# M460_v1 register map
File version: 1.0
Registers are 32-bit, read-write, reset 0x0 unless marked. A register's access mark holds for its fields unless they carry their own. Offsets are from the block's base; [hi:lo] are bit positions; {n}, {i} and the like mark numbered series; 'fields as' and 'values as' point back to an identical list.

## SYS (part 1 of 2) — SYS Register Map
Base 0x40000000
0x00 SYS_PDID ro reset 0x451A93 — Part Device Identification Number Register
  [31:0] PDID — Part Device Identification Number (Read Only). This register reflects device part number code. Software can read this register to identify which device is used.
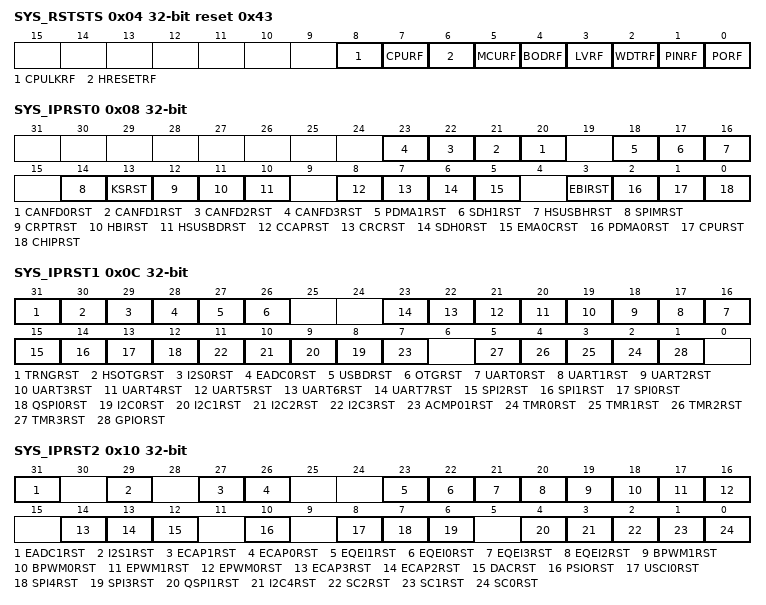
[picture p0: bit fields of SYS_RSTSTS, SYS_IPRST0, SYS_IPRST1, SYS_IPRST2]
0x04 SYS_RSTSTS reset 0x43 — System Reset Status Register
  [8] CPULKRF — CPU Lockup Reset Flag. Note 1: Write 1 to clear this bit to 0. Note 2: When CPU lockup happened under ICE is connected, this flag will set to 1 but chip will not reset.
    0=No reset from CPU lockup happened; 1=The Cortex-M4 lockup happened and chip is reset
  [7] CPURF — CPU Reset Flag. The CPU reset flag is set by hardware if software writes CPURST (SYS_IPRST0[1]) 1 to reset Cortex-M4 Core and Flash Memory Controller (FMC). Note: Write 1 to clear this bit to 0.
    0=No reset from CPU; 1=The Cortex-M4 Core and FMC are reset by software setting CPURST to 1
  [6] HRESETRF — HRESET Reset Flag. The HRESET reset flag is set by the 'Reset Signal' from the HRESET. Note 1: Write 1 to clear this bit to 0. Note 2: HRESET includes: POR, Reset Pin, LVR, BOD, WDT, WWDT, CPU lockup, CHIP and MCU reset.
    0=No reset from HRESET; 1=Reset from HRESET
  [5] MCURF — MCU Reset Flag. The MCU reset flag is set by the 'Reset Signal' from the Cortex-M4 Core to indicate the previous reset source. Note: Write 1 to clear this bit to 0.
    0=No reset from Cortex-M4; 1=The Cortex-M4 had issued the reset signal to reset the system by writing 1 to the bit SYSRESETREQ(AIRCR[2], Application Interrupt and Reset Control Register, address = 0xE000ED0C) in system control registers of Cortex-M4 core
  [4] BODRF — BOD Reset Flag. The BOD reset flag is set by the 'Reset Signal' from the Brown-Out Detector to indicate the previous reset source. Note: Write 1 to clear this bit to 0.
    0=No reset from BOD; 1=The BOD had issued the reset signal to reset the system
  [3] LVRF — LVR Reset Flag. The LVR reset flag is set by the 'Reset Signal' from the Low Voltage Reset Controller to indicate the previous reset source. Note: Write 1 to clear this bit to 0.
    0=No reset from LVR; 1=LVR controller had issued the reset signal to reset the system
  [2] WDTRF — WDT Reset Flag. The WDT reset flag is set by the 'Reset Signal' from the Watchdog Timer or Window Watchdog Timer to indicate the previous reset source. Note 1: Write 1 to clear this bit to 0. Note 2: Watchdog Timer register RSTF(WDT_CTL[2]) bit is set if the system has been reset by WDT time-out reset. Window Watchdog Timer register WWDTRF(WWDT_STATUS[1]) bit is set if the system has been reset by WWDT time-out reset.
    0=No reset from watchdog timer or window watchdog timer; 1=The watchdog timer or window watchdog timer had issued the reset signal to reset the system
  [1] PINRF — NRESET Pin Reset Flag. The nRESET pin reset flag is set by the 'Reset Signal' from the nRESET pin to indicate the previous reset source. Note: Write 1 to clear this bit to 0.
    0=No reset from nRESET pin; 1=Pin nRESET had issued the reset signal to reset the system
  [0] PORF — POR Reset Flag. The POR reset flag is set by the 'Reset Signal' from the Power-on Reset (POR) Controller or bit CHIPRST (SYS_IPRST0[0]) to indicate the previous reset source. Note: Write 1 to clear this bit to 0.
    0=No reset from POR or CHIPRST; 1=Power-on Reset (POR) or CHIPRST had issued the reset signal to reset the system
0x08 SYS_IPRST0 — Peripheral Reset Control Register 0
  [n+20] CANFD{n}RST (n=0..3) — CANFD{n} Controller Reset (Write Protect). Setting this bit to 1 will generate a reset signal to the CANFD{n} controller. User needs to set this bit to 0 to release from reset state. Note: This bit is write protected. Refer to the SYS_REGLCTL register.
    0=CANFD{n} controller normal operation; 1=CANFD{n} controller reset
  [18] PDMA1RST — PDMA1 Controller Reset (Write Protect). Setting this bit to 1 will generate a reset signal to the PDMA1 controller. User needs to set this bit to 0 to release from reset state. Note: This bit is write protected. Refer to the SYS_REGLCTL register.
    0=PDMA1 controller normal operation; 1=PDMA1 controller reset
  [17] SDH1RST — SDH1 Controller Reset (Write Protect). Setting this bit to 1 will generate a reset signal to the SDH1 controller. User needs to set this bit to 0 to release from the reset state. Note: This bit is write protected. Refer to the SYS_REGLCTL register.
    0=SDH1 controller normal operation; 1=SDH1 controller reset
  [16] HSUSBHRST — HSUSBH Controller Reset (Write Protect). Set this bit to 1 will generate a reset signal to the HSUSBH controller. User needs to set this bit to 0 to release from the reset state. Note: This bit is write protected. Refer to the SYS_REGLCTL register.
    0=HSUSBH controller normal operation; 1=HSUSBH controller reset
  [14] SPIMRST — SPIM Controller Reset (Write Protect). Setting this bit to 1 will generate a reset signal to the SPIM controller. User needs to set this bit to 0 to release from the reset state. Note: This bit is write protected. Refer to the SYS_REGLCTL register.
    0=SPIM controller normal operation; 1=SPIM controller reset
  [13] KSRST — Key Store Controller Reset (Write Protect). Setting this bit to 1 will generate a reset signal to the Key Store controller. User needs to set this bit to 0 to release from the reset state. Note: This bit is write protected. Refer to the SYS_REGLCTL register.
    0=Key Store controller normal operation; 1=Key Store controller reset
  [12] CRPTRST — CRYPTO Controller Reset (Write Protect). Setting this bit to 1 will generate a reset signal to the CRYPTO controller. User needs to set this bit to 0 to release from the reset state. Note: This bit is write protected. Refer to the SYS_REGLCTL register.
    0=CRYPTO controller normal operation; 1=CRYPTO controller reset
  [11] HBIRST — HBI Controller Reset (Write Protect). Setting this bit to 1 will generate a reset signal to the HBI controller. User needs to set this bit to 0 to release from the reset state. Note: This bit is write protected. Refer to the SYS_REGLCTL register.
    0=HBI controller normal operation; 1=HBI controller reset
  [10] HSUSBDRST — HSUSBD Controller Reset (Write Protect). Setting this bit to 1 will generate a reset signal to the HSUSBD controller. User needs to set this bit to 0 to release from the reset state.
    0=HSUSBD controller normal operation; 1=HSUSBD controller reset
  [8] CCAPRST — CCAP Controller Reset (Write Protect). Set this bit to 1 will generate a reset signal to the CCAP controller. User needs to set this bit to 0 to release from the reset state. Note: This bit is write protected. Refer to the SYS_REGLCTL register.
    0=CCAP controller normal operation; 1=CCAP controller reset
  [7] CRCRST — CRC Calculation Controller Reset (Write Protect). Set this bit to 1 will generate a reset signal to the CRC calculation controller. User needs to set this bit to 0 to release from the reset state. Note: This bit is write protected. Refer to the SYS_REGLCTL register.
    0=CRC calculation controller normal operation; 1=CRC calculation controller reset
  [6] SDH0RST — SDH0 Controller Reset (Write Protect). Setting this bit to 1 will generate a reset signal to the SDH0 controller. User needs to set this bit to 0 to release from the reset state. Note: This bit is write protected. Refer to the SYS_REGLCTL register.
    0=SDH0 controller normal operation; 1=SDH0 controller reset
  [5] EMA0CRST — EMAC0 Controller Reset (Write Protect). Setting this bit to 1 will generate a reset signal to the EMAC0 controller. User needs to set this bit to 0 to release from the reset state. Note: This bit is write protected. Refer to the SYS_REGLCTL register.
    0=EMAC0 controller normal operation; 1=EMAC0 controller reset
  [3] EBIRST — EBI Controller Reset (Write Protect). Set this bit to 1 will generate a reset signal to the EBI controller. User needs to set this bit to 0 to release from the reset state. Note: This bit is write protected. Refer to the SYS_REGLCTL register.
    0=EBI controller normal operation; 1=EBI controller reset
  [2] PDMA0RST — PDMA0 Controller Reset (Write Protect). Setting this bit to 1 will generate a reset signal to the PDMA0 controller. User needs to set this bit to 0 to release from reset state. Note: This bit is write protected. Refer to the SYS_REGLCTL register.
    0=PDMA0 controller normal operation; 1=PDMA0 controller reset
  [1] CPURST — Processor Core One-shot Reset (Write Protect). Setting this bit will only reset the processor core and Flash Memory Controller(FMC), and this bit will automatically return to 0 after the 2 clock cycles. Note: This bit is write protected. Refer to the SYS_REGLCTL register.
    0=Processor core normal operation; 1=Processor core one-shot reset
  [0] CHIPRST — Chip One-shot Reset (Write Protect). Setting this bit will reset the whole chip, including Processor core and all peripherals, and this bit will automatically return to 0 after the 2 clock cycles. The CHIPRST is same as the POR reset, all the chip controllers are reset and the chip setting from Flash are also reload. About the difference between CHIPRST and SYSRESETREQ(AIRCR[2]), please refer to System Reset section. Note: This bit is write protected. Refer to the SYS_REGLCTL register.
    0=Chip normal operation; 1=Chip one-shot reset
0x0C SYS_IPRST1 — Peripheral Reset Control Register 1
  [31] TRNGRST — TRNG Controller Reset
    0=TRNG controller normal operation; 1=TRNG controller reset
  [30] HSOTGRST — HSOTG Controller Reset
    0=HSOTG controller normal operation; 1=HSOTG controller reset
  [29] I2S0RST — I2S0 Controller Reset
    0=I2S0 controller normal operation; 1=I2S0 controller reset
  [28] EADC0RST — EADC0 Controller Reset
    0=EADC0 controller normal operation; 1=EADC0 controller reset
  [27] USBDRST — USBD Controller Reset
    0=USBD controller normal operation; 1=USBD controller reset
  [26] OTGRST — OTG Controller Reset
    0=OTG controller normal operation; 1=OTG controller reset
  [n+16] UART{n}RST (n=0..7) — UART{n} Controller Reset
    0=UART{n} controller normal operation; 1=UART{n} controller reset
  [15] SPI2RST — SPI2 Controller Reset
    0=SPI2 controller normal operation; 1=SPI2 controller reset
  [14] SPI1RST — SPI1 Controller Reset
    0=SPI1 controller normal operation; 1=SPI1 controller reset
  [13] SPI0RST — SPI0 Controller Reset
    0=SPI0 controller normal operation; 1=SPI0 controller reset
  [12] QSPI0RST — QSPI0 Controller Reset
    0=QSPI0 controller normal operation; 1=QSPI0 controller reset
  [n+8] I2C{n}RST (n=0..3) — I2C{n} Controller Reset
    0=I2C{n} controller normal operation; 1=I2C{n} controller reset
  [7] ACMP01RST — Analog Comparator 0/1 Controller Reset
    0=Analog Comparator 0/1 controller normal operation; 1=Analog Comparator 0/1 controller reset
  [n+2] TMR{n}RST (n=0..3) — Timer{n} Controller Reset
    0=Timer{n} controller normal operation; 1=Timer{n} controller reset
  [1] GPIORST — GPIO Controller Reset
    0=GPIO controller normal operation; 1=GPIO controller reset
0x10 SYS_IPRST2 — Peripheral Reset Control Register 2
  [31] EADC1RST — EADC1 Controller Reset
    0=EADC1 controller normal operation; 1=EADC1 controller reset
  [29] I2S1RST — I2S1 Controller Reset
    0=I2S1 controller normal operation; 1=I2S1 controller reset
  [27] ECAP1RST — ECAP1 Controller Reset
    0=ECAP1 controller normal operation; 1=ECAP1 controller reset
  [26] ECAP0RST — ECAP0 Controller Reset
    0=ECAP0 controller normal operation; 1=ECAP0 controller reset
  [23] EQEI1RST — EQEI1 Controller Reset
    0=EQEI1 controller normal operation; 1=EQEI1 controller reset
  [22] EQEI0RST — EQEI0 Controller Reset
    0=EQEI0 controller normal operation; 1=EQEI0 controller reset
  [21] EQEI3RST — EQEI3 Controller Reset
    0=EQEI3 controller normal operation; 1=EQEI3 controller reset
  [20] EQEI2RST — EQEI2 Controller Reset
    0=EQEI2 controller normal operation; 1=EQEI2 controller reset
  [19] BPWM1RST — BPWM1 Controller Reset
    0=BPWM1 controller normal operation; 1=BPWM1 controller reset
  [18] BPWM0RST — BPWM0 Controller Reset
    0=BPWM0 controller normal operation; 1=BPWM0 controller reset
  [17] EPWM1RST — EPWM1 Controller Reset
    0=EPWM1 controller normal operation; 1=EPWM1 controller reset
  [16] EPWM0RST — EPWM0 Controller Reset
    0=EPWM0 controller normal operation; 1=EPWM0 controller reset
  [14] ECAP3RST — ECAP3 Controller Reset
    0=ECAP3 controller normal operation; 1=ECAP3 controller reset
  [13] ECAP2RST — ECAP2 Controller Reset
    0=ECAP2 controller normal operation; 1=ECAP2 controller reset
  [12] DACRST — DAC Controller Reset
    0=DAC controller normal operation; 1=DAC controller reset
  [10] PSIORST — PSIO Controller Reset
    0=PSIO controller normal operation; 1=PSIO controller reset
  [8] USCI0RST — USCI0 Controller Reset
    0=USCI0 controller normal operation; 1=USCI0 controller reset
  [7] SPI4RST — SPI4 Controller Reset
    0=SPI4 controller normal operation; 1=SPI4 controller reset
  [6] SPI3RST — SPI3 Controller Reset
    0=SPI3 controller normal operation; 1=SPI3 controller reset
  [4] QSPI1RST — QSPI1 Controller Reset
    0=QSPI1 controller normal operation; 1=QSPI1 controller reset
  [3] I2C4RST — I2C4 Controller Reset
    0=I2C4 controller normal operation; 1=I2C4 controller reset
  [2] SC2RST — SC2 Controller Reset
    0=SC2 controller normal operation; 1=SC2 controller reset
  [1] SC1RST — SC1 Controller Reset
    0=SC1 controller normal operation; 1=SC1 controller reset
  [0] SC0RST — SC0 Controller Reset
    0=SC0 controller normal operation; 1=SC0 controller reset
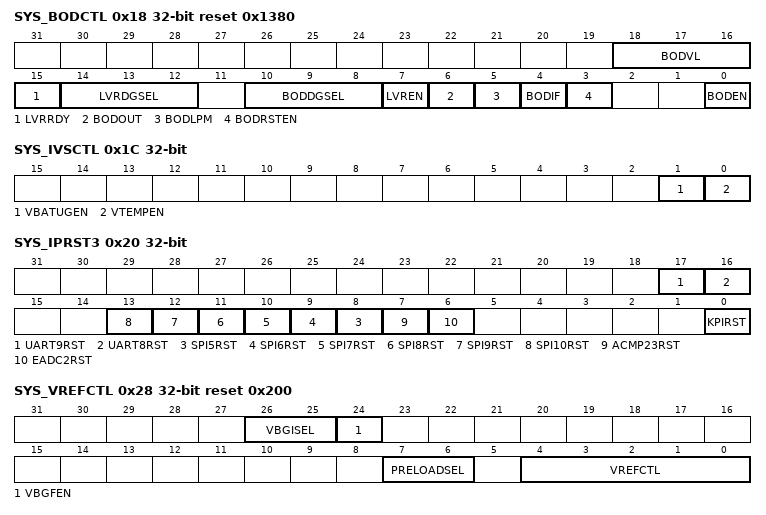
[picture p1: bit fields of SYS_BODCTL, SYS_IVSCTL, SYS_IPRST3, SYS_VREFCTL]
0x18 SYS_BODCTL reset 0x1380 (reset mask 0xFFF0FFF0) — Brown-out Detector Control Register
  [18:16] BODVL — Brown-out Detector Threshold Voltage Selection (Write Protect). The default value is set by Flash controller user configuration register CBOV (CONFIG0 [23:21]). Note: These bits are write protected. Refer to the SYS_REGLCTL register.
    0=Brown-Out Detector threshold voltage is 1.6V; 1=Brown-Out Detector threshold voltage is 1.8V; 2=Brown-Out Detector threshold voltage is 2.0V; 3=Brown-Out Detector threshold voltage is 2.2V; 4=Brown-Out Detector threshold voltage is 2.4V; 5=Brown-Out Detector threshold voltage is 2.6V; 6=Brown-Out Detector threshold voltage is 2.8V; 7=Brown-Out Detector threshold voltage is 3.0V
  [15] LVRRDY ro — Low Voltage Reset Ready Flag (Read Only). When the LVR function first enable, need more HCLK to wait LVR ready.
    0=Low Voltage Reset function not ready; 1=Low Voltage Reset function ready
  [14:12] LVRDGSEL — LVR Output De-glitch Time Select (Write Protect). Note: These bits are write protected. Refer to the SYS_REGLCTL register.
    0=Without de-glitch function; 1=4 system clock (HCLK); 2=8 system clock (HCLK); 3=16 system clock (HCLK); 4=32 system clock (HCLK); 5=64 system clock (HCLK); 6=128 system clock (HCLK); 7=256 system clock (HCLK)
  [10:8] BODDGSEL — Brown-out Detector Output De-glitch Time Select (Write Protect). Note: These bits are write protected. Refer to the SYS_REGLCTL register.
    0=BOD output is sampled by LIRC clock; 1=4 system clock (HCLK); 2=8 system clock (HCLK); 3=16 system clock (HCLK); 4=32 system clock (HCLK); 5=64 system clock (HCLK); 6=128 system clock (HCLK); 7=256 system clock (HCLK)
  [7] LVREN — Low Voltage Reset Enable Bit (Write Protect). The LVR function resets the chip when the input power voltage is lower than LVR circuit setting. LVR function is enabled by default. Note 1: After enabling the bit, the LVR function will be active with 100us ~ 200us delay for LVR output stable. LVRRDY(SYS_BODCTL[15]) is used to indicate LVR ready status. Note 2: This bit is write protected. Refer to the SYS_REGLCTL register.
    0=Low Voltage Reset function Disabled; 1=Low Voltage Reset function Enabled
  [6] BODOUT — Brown-out Detector Output Status. It means the detected voltage is lower than BODVL setting. If the BODEN is 0, BOD function disabled, this bit always responds 0.
    0=Brown-out Detector output status is 0; 1=Brown-out Detector output status is 1
  [5] BODLPM — Brown-out Detector Low Power Mode (Write Protect). Note 1: The BOD consumes about 100uA in normal mode, the low power mode can reduce the current to about 1/10 but slow the BOD response. Note 2: This bit is write protected. Refer to the SYS_REGLCTL register.
    0=BOD operate in normal mode (default); 1=BOD Low Power mode Enabled
  [4] BODIF — Brown-out Detector Interrupt Flag. Note: Write 1 to clear this bit to 0.
    0=Brown-out Detector does not detect any voltage draft at VDD down through or up through the voltage of BODVL setting; 1=When Brown-out Detector detects the VDD is dropped down through the voltage of BODVL setting or the VDD is raised up through the voltage of BODVL setting, this bit is set to 1 and the brown-out interrupt is requested if brown-out interrupt is enabled
  [3] BODRSTEN — Brown-out Reset Enable Bit (Write Protect). The default value is set by Flash controller user configuration register CBORST(CONFIG0[20]) bit. Note 1: While the Brown-out Detector function is enabled (BODEN high) and BOD reset function is enabled (BODRSTEN high), BOD will assert a signal to reset chip when the detected voltage is lower than the threshold (BODOUT high). While the BOD function is enabled (BODEN high) and BOD interrupt function is enabled (BODRSTEN low), BOD will assert an interrupt if BODOUT is high. BOD interrupt will keep till to the BODEN set to 0. BOD interrupt can be blocked by disabling the NVIC BOD interrupt or disabling BOD function (set BODEN low). Note 2: This bit is write protected. Refer to the SYS_REGLCTL register.
    0=Brown-out 'INTERRUPT' function Enabled; 1=Brown-out 'RESET' function Enabled
  [0] BODEN — Brown-out Detector Enable Bit (Write Protect). The default value is set by Flash controller user configuration register CBODEN (CONFIG0 [19]). Note: This bit is write protected. Refer to the SYS_REGLCTL register.
    0=Brown-out Detector function Disabled; 1=Brown-out Detector function Enabled
0x1C SYS_IVSCTL — Internal Voltage Source Control Register
  [1] VBATUGEN — VBAT Unity Gain Buffer Enable Bit. This bit is used to enable/disable VBAT unity gain buffer function. Note: After this bit is set to 1, the value of VBAT unity gain buffer output voltage can be obtained from ADC conversion result.
    0=VBAT unity gain buffer function Disabled (default); 1=VBAT unity gain buffer function Enabled
  [0] VTEMPEN — Temperature Sensor Enable Bit. This bit is used to enable/disable temperature sensor function.
    0=Temperature sensor function Disabled (default); 1=Temperature sensor function Enabled
0x20 SYS_IPRST3 — Peripheral Reset Control Register 3
  [17] UART9RST — UART9 Controller Reset
    0=UART9 controller normal operation; 1=UART9 controller reset
  [16] UART8RST — UART8 Controller Reset
    0=UART8 controller normal operation; 1=UART8 controller reset
  [n+3] SPI{n}RST (n=5..10) — SPI{n} Controller Reset
    0=SPI{n} controller normal operation; 1=SPI{n} controller reset
  [7] ACMP23RST — Analog Comparator 2/3 Controller Reset
    0=Analog Comparator 2/3 controller normal operation; 1=Analog Comparator 2/3 controller reset
  [6] EADC2RST — EADC2 Controller Reset
    0=EADC2 controller normal operation; 1=EADC2 controller reset
  [0] KPIRST — KPI Controller Reset
    0=KPI controller normal operation; 1=KPI controller reset
0x24 SYS_PORCTL — Power-On-reset Controller Register
  [15:0] POROFF — Power-on Reset Enable Bit (Write Protect). When powered on, the POR circuit generates a reset signal to reset the whole chip function, but noise on the power may cause the POR active again. User can disable internal POR circuit to avoid unpredictable noise to cause chip reset by writing 0x5AA5 to this field. The POR function will be active again when this field is set to another value or chip is reset by other reset source, including: nRESET, Watchdog, LVR reset, BOD reset, ICE reset command and the software-chip reset function. Note 1: Need to disable LVR by setting LVREN(SYS_BODCTL[7]) to 0 when setting POROFF(SYS_PORCTL[15:0]) to 0x5AA5. Note 2: These bits are write protected. Refer to the SYS_REGLCTL register.
0x28 SYS_VREFCTL reset 0x200 — VREF Control Register
  [26:25] VBGISEL — Chip Internal Voltage Band-gap Current Selection Bits (Write Protect). Note 1: When ADC conversion source select band-gap voltage, suggest set VBGISEL as 10. Note 2: These bits are write protected. Refer to the SYS_REGLCTL register.
    0=Band-gap voltage buffer current is 4.2uA; 1=Band-gap voltage buffer current is 7.3uA; 2=Band-gap voltage buffer current is 10.4uA; 3=Band-gap voltage buffer current is 13.5uA
  [24] VBGFEN — Chip Internal Voltage Band-gap Force Enable Bit (Write Protect). Note: This bit is write protected. Refer to the SYS_REGLCTL register.
    0=Chip internal voltage band-gap controlled by ADC/ACMP if source selected; 1=Chip internal voltage band-gap force enable
  [7:6] PRELOADSEL — Pre-load Timing Selection (Write Protect). Note: These bits are write protected. Refer to the SYS_REGLCTL register.
    0=Pre-load time is 60us for 0.1uF Capacitor; 1=Pre-load time is 310us for 1uF Capacitor; 2=Pre-load time is 1270us for 4.7uF Capacitor; 3=Pre-load time is 2650us for 10uF Capacitor
  [4:0] VREFCTL — VREF Control Bits (Write Protect). Note: These bits are write protected. Refer to the SYS_REGLCTL register.
    0=VREF is from external pin; 3=VREF is internal 1.6V; 7=VREF is internal 2.0V; 11=VREF is internal 2.5V; 15=VREF is internal 3.0V
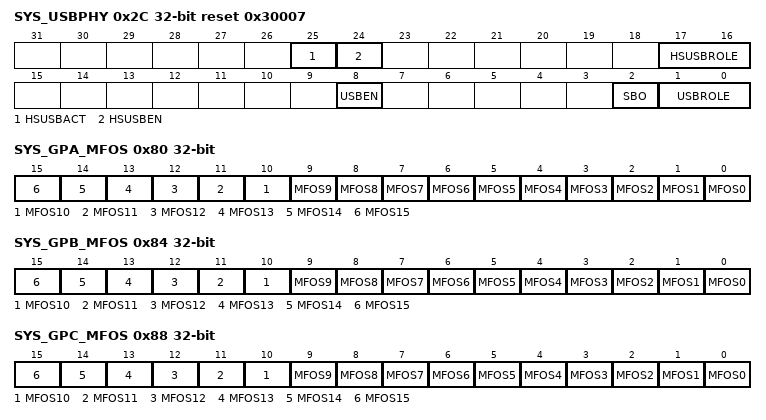
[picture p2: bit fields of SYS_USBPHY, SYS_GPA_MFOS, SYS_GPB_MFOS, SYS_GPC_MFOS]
0x2C SYS_USBPHY reset 0x30007 — USB PHY Control Register
  [25] HSUSBACT — HSUSB PHY Active Control. This bit is used to control HSUSB PHY at reset state or active state. Note: After setting HSUSBEN (SYS_USBPHY[24]) to enable HSUSB PHY, user should keep HSUSB PHY at reset mode at lease 10us before changing to active mode.
    0=HSUSB PHY at reset state; 1=HSUSB PHY at active state
  [24] HSUSBEN — HSUSB PHY Enable. This bit is used to enable/disable HSUSB PHY.
    0=HSUSB PHY Disabled; 1=HSUSB PHY Enabled
  [17:16] HSUSBROLE — HSUSB Role Option (Write Protect). These two bits are used to select the role of HSUSB. Note: These bits are write protected. Refer to the SYS_REGLCTL register.
    0=Standard HSUSB Device mode; 1=Standard HSUSB Host mode; 2=ID dependent mode; 3=On-The-Go device mode
  [8] USBEN — USB PHY Enable. This bit is used to enable/disable USB PHY.
    0=USB PHY Disabled; 1=USB PHY Enabled
  [2] SBO — Note: This bit must always be kept 1. If set to 0, the result is unpredictable.
  [1:0] USBROLE — USB Role Option (Write Protect). These two bits are used to select the role of USB. Note: These bits are write protected. Refer to the SYS_REGLCTL register.
    0=Standard USB Device mode; 1=Standard USB Host mode; 2=ID dependent mode; 3=On-The-Go device mode
0x80 SYS_GPA_MFOS — GPIOA Multiple Function Output Select Register
  [all] fields
    0=Multiple function pin output mode type is Push-pull mode; 1=Multiple function pin output mode type is Open-drain mode
  [n] MFOS{n} (n=0..15) — GPIOA-J Pin[n] Multiple Function Pin Output Mode Select. This bit used to select multiple function pin output mode type for Px.n pin.
0x84 SYS_GPB_MFOS — GPIOB Multiple Function Output Select Register
  fields as SYS_GPA_MFOS
0x88 SYS_GPC_MFOS — GPIOC Multiple Function Output Select Register
  fields as SYS_GPA_MFOS
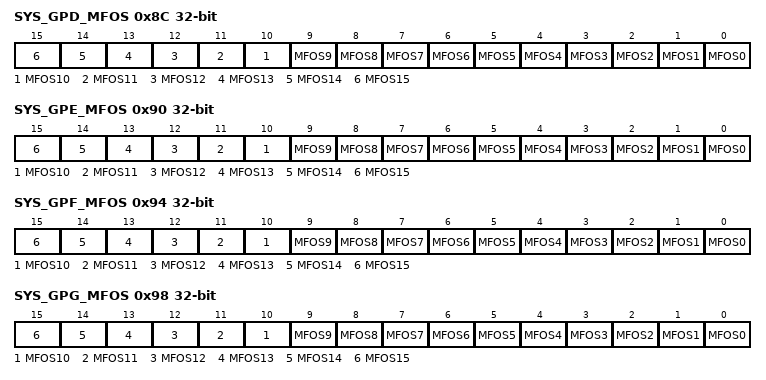
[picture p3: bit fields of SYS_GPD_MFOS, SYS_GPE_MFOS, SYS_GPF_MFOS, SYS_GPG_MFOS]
0x8C SYS_GPD_MFOS — GPIOD Multiple Function Output Select Register
  fields as SYS_GPA_MFOS
0x90 SYS_GPE_MFOS — GPIOE Multiple Function Output Select Register
  fields as SYS_GPA_MFOS
0x94 SYS_GPF_MFOS — GPIOF Multiple Function Output Select Register
  fields as SYS_GPA_MFOS
0x98 SYS_GPG_MFOS — GPIOG Multiple Function Output Select Register
  fields as SYS_GPA_MFOS
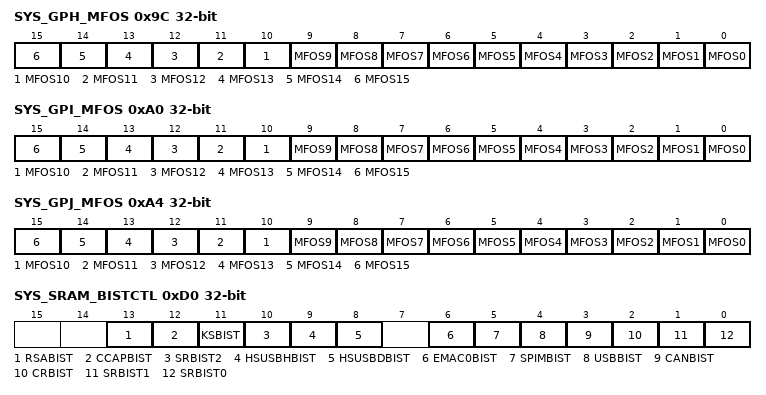
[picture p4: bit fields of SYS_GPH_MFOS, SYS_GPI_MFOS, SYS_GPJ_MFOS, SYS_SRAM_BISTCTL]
0x9C SYS_GPH_MFOS — GPIOH Multiple Function Output Select Register
  fields as SYS_GPA_MFOS
0xA0 SYS_GPI_MFOS — GPIOI Multiple Function Output Select Register
  fields as SYS_GPA_MFOS
0xA4 SYS_GPJ_MFOS — GPIOJ Multiple Function Output Select Register
  fields as SYS_GPA_MFOS
0xC0 SYS_SRAM_INTCTL — System SRAM Interrupt Enable Control Register
  [0] PERRIEN — SRAM Parity Check Error Interrupt Enable Bit
    0=SRAM parity check error interrupt Disabled; 1=SRAM parity check error interrupt Enabled
0xC4 SYS_SRAM_STATUS — System SRAM Parity Error Status Register
  [0] PERRIF — SRAM Parity Check Error Flag. This bit indicates the System SRAM parity error occurred. Write 1 to clear this to 0.
    0=No System SRAM parity error; 1=System SRAM parity error occur
0xC8 SYS_SRAM_ERRADDR ro — System SRAM Parity Check Error Address Register
  [31:0] ERRADDR — System SRAM Parity Error Address (Read Only). This register shows system SRAM parity error byte address.
0xD0 SYS_SRAM_BISTCTL — System SRAM BIST Test Control Register
  [13] RSABIST — RSA SRAM BIST Enable Bit (Write Protect). This bit enables BIST test for RSA SRAM. Note: This bit is write protected. Refer to the SYS_REGLCTL register.
    0=RSA SRAM BIST Disabled; 1=RSA SRAM BIST Enabled
  [12] CCAPBIST — CCAP SRAM BIST Enable Bit (Write Protect). This bit enables BIST test for CCAP SRAM. Note: This bit is write protected. Refer to the SYS_REGLCTL register.
    0=CCAP SRAM BIST Disabled; 1=CCAP SRAM BIST Enabled
  [11] KSBIST — Key Store SRAM BIST Enable Bit (Write Protect). This bit enables BIST test for Key Store SRAM. Note: This bit is write protected. Refer to the SYS_REGLCTL register.
    0=Key Store SRAM BIST Disabled; 1=Key Store SRAM BIST Enabled
  [10] SRBIST2 — System SRAM Bank2 BIST Enable Bit (Write Protect). This bit enables BIST test for system SRAM bank2. Note: This bit is write protected. Refer to the SYS_REGLCTL register.
    0=System SRAM bank2 BIST Disabled; 1=System SRAM bank2 BIST Enabled
  [9] HSUSBHBIST — HSUSBH SRAM BIST Enable Bit (Write Protect). This bit enables BIST test for HSUSBH SRAM. Note: This bit is write protected. Refer to the SYS_REGLCTL register.
    0=HSUSBH SRAM BIST Disabled; 1=HSUSBH SRAM BIST Enabled
  [8] HSUSBDBIST — HSUSBD SRAM BIST Enable Bit (Write Protect). This bit enables BIST test for HSUSBD SRAM. Note: This bit is write protected. Refer to the SYS_REGLCTL register.
    0=HSUSBD SRAM BIST Disabled; 1=HSUSBD SRAM BIST Enabled
  [6] EMAC0BIST — EMAC0 SRAM BIST Enable Bit (Write Protect). This bit enables BIST test for EMAC0 SRAM. Note: This bit is write protected. Refer to the SYS_REGLCTL register.
    0=EMAC0 SRAM BIST Disabled; 1=EMAC0 SRAM BIST Enabled
  [5] SPIMBIST — SPIM SRAM BIST Enable Bit (Write Protect). This bit enables BIST test for SPIM SRAM. Note: This bit is write protected. Refer to the SYS_REGLCTL register.
    0=SPIM SRAM BIST Disabled; 1=SPIM SRAM BIST Enabled
  [4] USBBIST — USB SRAM BIST Enable Bit (Write Protect). This bit enables BIST test for USB SRAM. Note: This bit is write protected. Refer to the SYS_REGLCTL register.
    0=USB SRAM BIST Disabled; 1=USB SRAM BIST Enabled
  [3] CANBIST — CAN SRAM BIST Enable Bit (Write Protect). This bit enables BIST test for CAN SRAM. Note: This bit is write protected. Refer to the SYS_REGLCTL register.
    0=CAN SRAM BIST Disabled; 1=CAN SRAM BIST Enabled
  [2] CRBIST — CACHE SRAM BIST Enable Bit (Write Protect). This bit enables BIST test for CACHE SRAM. Note: This bit is write protected. Refer to the SYS_REGLCTL register.
    0=CACHE SRAM BIST Disabled; 1=CACHE SRAM BIST Enabled
  [1] SRBIST1 — System SRAM Bank1 BIST Enable Bit (Write Protect). This bit enables BIST test for system SRAM bank1. Note: This bit is write protected. Refer to the SYS_REGLCTL register.
    0=System SRAM bank1 BIST Disabled; 1=System SRAM bank1 BIST Enabled
  [0] SRBIST0 — System SRAM Bank0 BIST Enable Bit (Write Protect). This bit enables BIST test for system SRAM bank0. Note: This bit is write protected. Refer to the SYS_REGLCTL register.
    0=System SRAM bank0 BIST Disabled; 1=System SRAM bank0 BIST Enabled
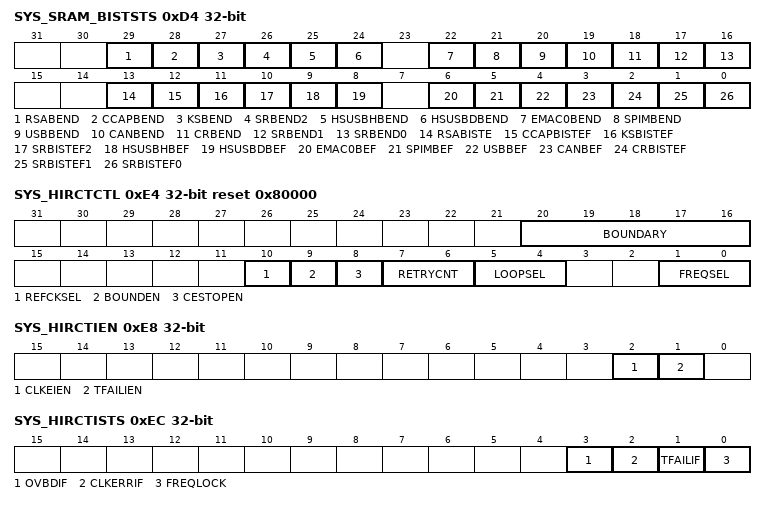
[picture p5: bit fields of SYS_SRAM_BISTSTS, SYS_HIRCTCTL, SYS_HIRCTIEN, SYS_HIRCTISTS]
0xD4 SYS_SRAM_BISTSTS ro (reset mask 0xFF00FF00) — System SRAM BIST Test Status Register
  [29] RSABEND — RSA SRAM BIST Test Finish (Read Only)
    0=RSA SRAM BIST is active; 1=RSA SRAM BIST test finish
  [28] CCAPBEND — CCAP BIST Test Finish (Read Only)
    0=CCAP SRAM BIST is active; 1=CCAP SRAM BIST test finish
  [27] KSBEND — Key Store SRAM BIST Test Finish (Read Only)
    0=Key Store SRAM BIST is active; 1=Key Store SRAM BIST test finish
  [26] SRBEND2 — System SRAM Bnak2 BIST Test Finish (Read Only)
    0=System SRAM bank2 BIST is active; 1=System SRAM bank2 BIST finish
  [25] HSUSBHBEND — HSUSBH SRAM BIST Test Finish (Read Only)
    0=HSUSBH SRAM BIST is active; 1=HSUSBH SRAM BIST test finish
  [24] HSUSBDBEND — HSUSBD SRAM BIST Test Finish (Read Only)
    0=HSUSBD SRAM BIST is active; 1=HSUSBD SRAM BIST test finish
  [22] EMAC0BEND — EMAC0 SRAM BIST Test Finish (Read Only)
    0=EMAC0 SRAM BIST is active; 1=EMAC0 SRAM BIST test finish
  [21] SPIMBEND — SPIM SRAM BIST Test Finish (Read Only)
    0=SPIM SRAM BIST is active; 1=SPIM SRAM BIST test finish
  [20] USBBEND — USB SRAM BIST Test Finish (Read Only)
    0=USB SRAM BIST is active; 1=USB SRAM BIST test finish
  [19] CANBEND — CAN SRAM BIST Test Finish (Read Only). Note: All of the CAN SRAM macros BIST finish, this flag is 1.
    0=CAN SRAM BIST is active; 1=CAN SRAM BIST test finish
  [18] CRBEND — CACHE SRAM BIST Test Finish (Read Only)
    0=CACHE SRAM BIST is active; 1=CACHE SRAM BIST test finish
  [17] SRBEND1 — System SRAM Bnak1 BIST Test Finish (Read Only)
    0=System SRAM bank1 BIST is active; 1=System SRAM bank1 BIST finish
  [16] SRBEND0 — System SRAM Bank0 BIST Test Finish (Read Only)
    0=System SRAM bank0 BIST active; 1=System SRAM bank0 BIST finish
  [13] RSABISTE — RSA SRAM BIST Fail Flag (Read Only)
    0=RSA SRAM BIST test pass; 1=RSA SRAM BIST test fail
  [12] CCAPBISTEF — CCAP SRAM BIST Fail Flag (Read Only)
    0=CCAP SRAM BIST test pass; 1=CCAP SRAM BIST test fail
  [11] KSBISTEF — Key Store SRAM BIST Fail Flag (Read Only)
    0=Key Store SRAM BIST test pass; 1=Key Store SRAM BIST test fail
  [10] SRBISTEF2 — System Bnak2 SRAM BIST Fail Flag (Read Only)
    0=System SRAM bank2 BIST test pass; 1=System SRAM bank2 BIST test fail
  [9] HSUSBHBEF — HSUSBH SRAM BIST Fail Flag (Read Only)
    0=HSUSBH SRAM BIST test pass; 1=HSUSBH SRAM BIST test fail
  [8] HSUSBDBEF — HSUSBD SRAM BIST Fail Flag (Read Only)
    0=HSUSBD SRAM BIST test pass; 1=HSUSBD SRAM BIST test fail
  [6] EMAC0BEF — EMAC0 SRAM BIST Fail Flag (Read Only)
    0=EMAC0 SRAM BIST test pass; 1=EMAC0 SRAM BIST test fail
  [5] SPIMBEF — SPIM SRAM BIST Fail Flag (Read Only)
    0=SPIM SRAM BIST test pass; 1=SPIM SRAM BIST test fail
  [4] USBBEF — USB SRAM BIST Fail Flag (Read Only)
    0=USB SRAM BIST test pass; 1=USB SRAM BIST test fail
  [3] CANBEF — CAN SRAM BIST Fail Flag (Read Only). Note: Any of the CAN SRAM macros BIST fail, this flag is 1.
    0=CAN SRAM BIST test pass; 1=CAN SRAM BIST test fail
  [2] CRBISTEF — CACHE SRAM BIST Fail Flag (Read Only)
    0=CACHE RAM BIST test pass; 1=CACHE RAM BIST test fail
  [1] SRBISTEF1 — System SRAM Bank1 BIST Fail Flag (Read Only)
    0=System SRAM bank1 BIST test pass; 1=System SRAM bank1 BIST test fail
  [0] SRBISTEF0 — System SRAM Bank0 BIST Fail Flag (Read Only)
    0=System SRAM bank0 BIST test pass; 1=System SRAM bank0 BIST test fail
0xE4 SYS_HIRCTCTL reset 0x80000 — HIRC48M Trim Control Register
  [20:16] BOUNDARY — Boundary Selection. Fill the boundary range from 0x1 to 0x31, 0x0 is reserved. Note: This field is effective only when the BOUNDEN(SYS_HIRCTCTL[9]) is enabled.
  [10] REFCKSEL — Reference Clock Selection. Note: HIRC trim reference clock is 20 kHz in test mode.
    0=HIRC trim reference clock is from LXT (32.768 kHz); 1=HIRC trim reference clock is from internal USB synchronous mode
  [9] BOUNDEN — Boundary Enable Bit
    0=Boundary function Disabled; 1=Boundary function Enabled
  [8] CESTOPEN — Clock Error Stop Enable Bit
    0=The trim operation is keep going if clock is inaccuracy; 1=The trim operation is stopped if clock is inaccuracy
  [7:6] RETRYCNT — Trim Value Update Limitation Count. This field defines that how many times the auto trim circuit will try to update the HIRC trim value before the frequency of HIRC locked. Once the HIRC locked, the internal trim value update counter will be reset. If the trim value update counter reached this limitation value and frequency of HIRC still doesn't lock, the auto trim operation will be disabled and FREQSEL will be cleared to 00.
    0=Trim retry count limitation is 64 loops; 1=Trim retry count limitation is 128 loops; 2=Trim retry count limitation is 256 loops; 3=Trim retry count limitation is 512 loops
  [5:4] LOOPSEL — Trim Calculation Loop Selection. This field defines that trim value calculation is based on how many reference clocks. Note: For example, if LOOPSEL is set as 00, auto trim circuit will calculate trim value based on the average frequency difference in 4 clocks of reference clock.
    0=Trim value calculation is based on average difference in 4 clocks of reference clock; 1=Trim value calculation is based on average difference in 8 clocks of reference clock; 2=Trim value calculation is based on average difference in 16 clocks of reference clock; 3=Trim value calculation is based on average difference in 32 clocks of reference clock
  [1:0] FREQSEL — Trim Frequency Selection. This field indicates the target frequency of 48 MHz internal high speed RC oscillator (HIRC48M) auto trim. During auto trim operation, if clock error detected with CESTOPEN is set to 1 or trim retry limitation count reached, this field will be cleared to 00 automatically.
    0=Disable HIRC auto trim function; 1=Enable HIRC auto trim function and trim HIRC to 48 MHz
0xE8 SYS_HIRCTIEN — HIRC48M Trim Interrupt Enable Register
  [2] CLKEIEN — Clock Error Interrupt Enable Bit. This bit controls if CPU would get an interrupt while clock is inaccuracy during auto trim operation. If this bit is set to1, and CLKERRIF(SYS_HIRCTISTS[2]) is set during auto trim operation, an interrupt will be triggered to notify the clock frequency is inaccuracy.
    0=Disable CLKERRIF(SYS_HIRCTISTS[2]) status to trigger an interrupt to CPU; 1=Enable CLKERRIF(SYS_HIRCTISTS[2]) status to trigger an interrupt to CPU
  [1] TFAILIEN — Trim Failure Interrupt Enable Bit. This bit controls if an interrupt will be triggered while HIRC trim value update limitation count reached and HIRC frequency still not locked on target frequency set by FREQSEL(SYS_HIRCTCTL[1:0]). If this bit is high and TFAILIF(SYS_HIRCTISTS[1]) is set during auto trim operation, an interrupt will be triggered to notify that HIRC trim value update limitation count was reached.
    0=Disable TFAILIF(SYS_HIRCTISTS[1]) status to trigger an interrupt to CPU; 1=Enable TFAILIF(SYS_HIRCTISTS[1]) status to trigger an interrupt to CPU
0xEC SYS_HIRCTISTS — HIRC48M Trim Interrupt Status Register
  [3] OVBDIF — Over Boundary Status. When the over boundary function is set, if there occurs the over boundary condition, this flag will be set. Note: Write 1 to clear this flag.
    0=Over boundary condition did not occur; 1=Over boundary condition occurred
  [2] CLKERRIF — Clock Error Interrupt Status. When the frequency of 32.768 kHz external low speed crystal oscillator (LXT) or 48 MHz internal high speed RC oscillator (HIRC48M) is shift larger to unreasonable value, this bit will be set and to be an indicate that clock frequency is inaccuracy. Once this bit is set to 1, the auto trim operation stopped and FREQSEL(SYS_HIRCTCTL[1:0]) will be cleared to 00 by hardware automatically if CESTOPEN(SYS_HIRCTCTL[8]) is set to 1. If this bit is set and CLKEIEN(SYS_HIRCTIEN[2]) is high, an interrupt will be triggered to notify the clock frequency is inaccuracy. Write 1 to clear this to 0.
    0=Clock frequency is accuracy; 1=Clock frequency is inaccuracy
  [1] TFAILIF — Trim Failure Interrupt Status. This bit indicates that HIRC trim value update limitation count reached and the HIRC clock frequency still doesn't be locked. Once this bit is set, the auto trim operation stopped and FREQSEL(SYS_HIRCTCTL[1:0]) will be cleared to 00 by hardware automatically. If this bit is set and TFAILIEN(SYS_HIRCTIEN[1]) is high, an interrupt will be triggered to notify that HIRC trim value update limitation count was reached. Write 1 to clear this to 0.
    0=Trim value update limitation count does not reach; 1=Trim value update limitation count reached and HIRC frequency still not locked
  [0] FREQLOCK — HIRC Frequency Lock Status. This bit indicates the HIRC frequency is locked. This is a status bit and doesn't trigger any interrupt. Write 1 to clear this to 0. This bit will be set automatically, if the frequency is lock and the RC_TRIM is enabled.
    0=The internal high-speed oscillator frequency doesn't lock at 48 MHz yet; 1=The internal high-speed oscillator frequency locked at 48 MHz
